# ATxmega16E5 device description
Architecture: AVR8_XMEGA; Family: AVR XMEGA
Registers are 8-bit, access not given, no defined reset value unless marked. A register's access mark holds for its fields unless they carry their own. Offsets are from the block's base; [hi:lo] are bit positions; {n}, {i} and the like mark numbered series; 'fields as' and 'values as' point back to an identical list.

## HIRES — High-Resolution Extension
Instances: HIRESC 0x8B0
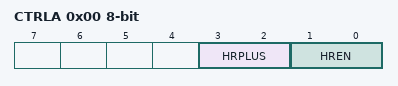
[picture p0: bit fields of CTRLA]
0x00 CTRLA — Control Register A
  [3:2] HRPLUS — High Resolution Plus
    0=NONE (No Hi-Res Plus); 1=HRP4 (Hi-Res Plus enabled on Timer 4); 2=HRP5 (Hi-Res Plus enabled on Timer 5); 3=BOTH (Hi-Res Plus enabled on Timer 4 and 5)
  [1:0] HREN — High Resolution Mode
    0=NONE (No Hi-Res); 1=HRP4 (Hi-Res enabled on Timer 4); 2=HRP5 (Hi-Res enabled on Timer 5); 3=BOTH (Hi-Res enabled on Timer 4 and 5)

## USART — Universal Synchronous/Asynchronous Receiver/Transmitter
Instances: USARTC0 0x8C0, USARTD0 0x9C0
0x00 DATA
0x01 STATUS
  [7] RXCIF — Receive Interrupt Flag
  [6] TXCIF — Transmit Interrupt Flag
  [5] DREIF — Data Register Empty Flag
  [4] FERR — Frame Error
  [3] BUFOVF — Buffer Overflow
  [2] PERR — Parity Error
  [1] RXSIF — Receive Start Bit Interrupt Flag
  [0] RXB8 — Receive Bit 8
  [0] DRIF — Data Reception Flag
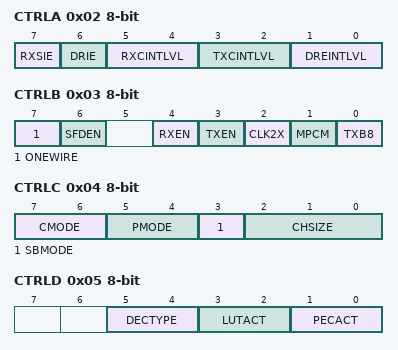
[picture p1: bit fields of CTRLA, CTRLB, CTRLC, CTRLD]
0x02 CTRLA — Control Register A
  [7] RXSIE — Receive Start Interrupt Enable
  [6] DRIE — Data Reception Interrupt Enable
  [5:4] RXCINTLVL — Receive Interrupt Level
    0=OFF (Interrupt Disabled); 1=LO (Low Level); 2=MED (Medium Level); 3=HI (High Level)
  [3:2] TXCINTLVL — Transmit Interrupt Level
    values as RXCINTLVL
  [1:0] DREINTLVL — Data Register Empty Interrupt Level
    values as RXCINTLVL
0x03 CTRLB — Control Register B
  [7] ONEWIRE — One Wire Mode
  [6] SFDEN — Start Frame Detection Enable
  [4] RXEN — Receiver Enable
  [3] TXEN — Transmitter Enable
  [2] CLK2X — Double transmission speed
  [1] MPCM — Multi-processor Communication Mode
  [0] TXB8 — Transmit bit 8
0x04 CTRLC — Control Register C
  [7:6] CMODE — Communication Mode
    0=ASYNCHRONOUS (Asynchronous Mode); 1=SYNCHRONOUS (Synchronous Mode); 2=IRDA (IrDA Mode); 3=MSPI (Master SPI Mode)
  [5:4] PMODE — Parity Mode
    0=DISABLED (No Parity); 2=EVEN (Even Parity); 3=ODD (Odd Parity)
  [3] SBMODE — Stop Bit Mode
  [2:0] CHSIZE — Character Size
    {v}={v+5}BIT (Character size: {v+5} bit) (v=0..3); 7=9BIT (Character size: 9 bit)
0x05 CTRLD — Control Register D
  [5:4] DECTYPE — Receive Interrupt Level
    0=DATA (DATA Field Encoding); 2=SDATA (Start and Data Fields Encoding); 3=NOTSDATA (Start and Data Fields Encoding, with invertion in START field)
  [3:2] LUTACT — Transmit Interrupt Level
    0=OFF (Standard Frame Configuration); 1=RX (Receiver Decoding Enabled); 2=TX (Transmitter Encoding Enabled); 3=BOTH (Both Encoding and Decoding Enabled)
  [1:0] PECACT — Data Register Empty Interrupt Level
    0=OFF (Standard Mode); 1=PEC0 (Variable Data Lenght in Reception); 2=PEC1 (Variable Data Lenght in Transmission); 3=PERC01 (Variable Data Lenght in both Reception and Transmission)
0x06 BAUDCTRLA — Baud Rate Control Register A
  [7:0] BSEL — Baud Rate Selection Bits [7:0]
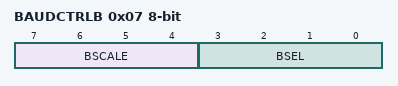
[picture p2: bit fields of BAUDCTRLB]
0x07 BAUDCTRLB — Baud Rate Control Register B
  [7:4] BSCALE — Baud Rate Scale
  [3:0] BSEL — Baud Rate Selection bits[11:8]

## SPI — Serial Peripheral Interface with Buffer Modes
Instances: SPIC 0x08E0
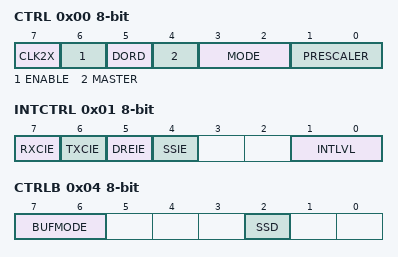
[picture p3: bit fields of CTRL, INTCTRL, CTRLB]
0x00 CTRL — Control Register
  [7] CLK2X — Enable Double Speed
  [6] ENABLE — Enable SPI Module
  [5] DORD — Data Order Setting
  [4] MASTER — Master Operation Enable
  [3:2] MODE — SPI Mode
    0=SPI Mode 0, base clock at "0", sampling on leading edge (rising) & set-up on trailling edge (falling); 1=SPI Mode 1, base clock at "0", set-up on leading edge (rising) & sampling on trailling edge (falling); 2=SPI Mode 2, base clock at "1", sampling on leading edge (falling) & set-up on trailling edge (rising); 3=SPI Mode 3, base clock at "1", set-up on leading edge (falling) & sampling on trailling edge (rising)
  [1:0] PRESCALER
    0=DIV4 (If CLK2X=1 CLKper/2, else (CLK2X=0) CLKper/4.); 1=DIV16 (If CLK2X=1 CLKper/8, else (CLK2X=0) CLKper/16.); 2=DIV64 (If CLK2X=1 CLKper/32, else (CLK2X=0) CLKper/64.); 3=DIV128 (If CLK2X=1 CLKper/64, else (CLK2X=0) CLKper/128.)
0x01 INTCTRL — Interrupt Control Register
  [7] RXCIE — Receive Complete Interrupt Enable (In Buffer Modes Only).
  [6] TXCIE — Transmit Complete Interrupt Enable (In Buffer Modes Only).
  [5] DREIE — Data Register Empty Interrupt Enable (In Buffer Modes Only).
  [4] SSIE — Slave Select Trigger Interrupt Enable (In Buffer Modes Only).
  [1:0] INTLVL — Interrupt level
    0=OFF (Interrupt Disabled); 1=LO (Low Level); 2=MED (Medium Level); 3=HI (High Level)
0x02 STATUS
  [7] IF — Interrupt Flag (In Standard Mode Only).
  [7] RXCIF — Receive Complete Interrupt Flag (In Buffer Modes Only).
  [6] WRCOL — Write Collision Flag (In Standard Mode Only).
  [6] TXCIF — Transmit Complete Interrupt Flag (In Buffer Modes Only).
  [5] DREIF — Data Register Empty Interrupt Flag (In Buffer Modes Only).
  [4] SSIF — Slave Select Trigger Interrupt Flag (In Buffer Modes Only).
  [0] BUFOVF — Buffer Overflow (In Buffer Modes Only).
0x03 DATA
0x04 CTRLB — Control Register B
  [7:6] BUFMODE — Buffer Modes
    0=OFF (SPI Unbuffered Mode); 2=Buffer Mode 1 (with dummy byte); 3=Buffer Mode 2 (no dummy byte)
  [2] SSD — Slave Select Disable

## IRCOM — IR Communication Module
Instances: IRCOM 0x8F8
0x00 CTRL — Control Register
  [3:0] EVSEL — Event Channel Select
    0=OFF (No Event Source); {v}=Event Channel {v-8} (v=8..15)
0x01 TXPLCTRL — IrDA Transmitter Pulse Length Control Register
0x02 RXPLCTRL — IrDA Receiver Pulse Length Control Register

## NVM_LOCKBITS (FUSE module) — Lock Bits
Instances: LOCKBIT 0x00 in lockbits
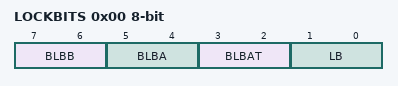
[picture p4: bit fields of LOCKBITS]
0x00 LOCKBITS
  [7:6] BLBB — Boot Lock Bits - Boot Section
    0=RWLOCK (Read and write not allowed); 1=RLOCK (Read not allowed); 2=WLOCK (Write not allowed); 3=NOLOCK (No locks)
  [5:4] BLBA — Boot Lock Bits - Application Section
    values as BLBB
  [3:2] BLBAT — Boot Lock Bits - Application Table
    values as BLBB
  [1:0] LB — Lock Bits
    0=RWLOCK (Read and write not allowed); 2=WLOCK (Write not allowed); 3=NOLOCK (No locks)

## NVM_FUSES — Fuses
Instances: FUSE 0x00 in fuses
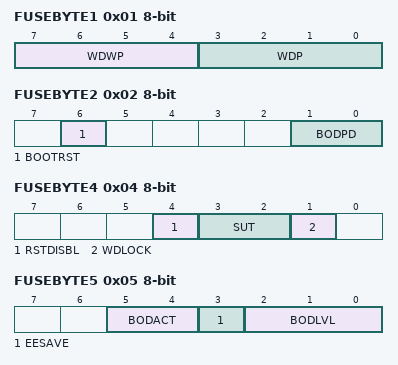
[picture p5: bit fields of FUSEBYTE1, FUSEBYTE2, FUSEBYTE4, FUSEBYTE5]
0x01 FUSEBYTE1 — Watchdog Configuration
  [7:4] WDWP — Watchdog Window Timeout Period
    0=8CLK (8 cycles (8ms @ 3.3V)); 1=16CLK (16 cycles (16ms @ 3.3V)); 2=32CLK (32 cycles (32ms @ 3.3V)); 3=64CLK (64 cycles (64ms @ 3.3V)); 4=128CLK (128 cycles (0.125s @ 3.3V)); 5=256CLK (256 cycles (0.25s @ 3.3V)); 6=512CLK (512 cycles (0.5s @ 3.3V)); 7=1KCLK (1K cycles (1s @ 3.3V)); 8=2KCLK (2K cycles (2s @ 3.3V)); 9=4KCLK (4K cycles (4s @ 3.3V)); 10=8KCLK (8K cycles (8s @ 3.3V))
  [3:0] WDP — Watchdog Timeout Period
    values as WDWP
0x02 FUSEBYTE2 — Reset Configuration
  [6] BOOTRST — Boot Loader Section Reset Vector
    0=BOOTLDR (Boot Loader Reset); 1=APPLICATION (Application Reset)
  [1:0] BODPD — BOD Operation in Power-Down Mode
    1=SAMPLED (BOD enabled in sampled mode); 2=CONTINUOUS (BOD enabled continuously); 3=DISABLED (BOD Disabled)
0x04 FUSEBYTE4 — Start-up Configuration
  [4] RSTDISBL — External Reset Disable
  [3:2] SUT — Start-up Time
    3=0MS; 1=4MS; 0=64MS
  [1] WDLOCK — Watchdog Timer Lock
0x05 FUSEBYTE5 — EESAVE and BOD Level
  [5:4] BODACT — BOD Operation in Active Mode
    values as FUSEBYTE2.BODPD
  [3] EESAVE — Preserve EEPROM Through Chip Erase
  [2:0] BODLVL — Brownout Detection Voltage Level
    7=1V6 (1.6 V); 6=1V8 (1.8 V); 5=2V0 (2.0 V); 4=2V2 (2.2 V); 3=2V4 (2.4 V); 2=2V6 (2.6 V); 1=2V8 (2.8 V); 0=3V0 (3.0 V)
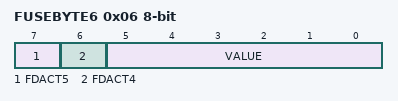
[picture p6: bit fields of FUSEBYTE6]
0x06 FUSEBYTE6 — Fault State
  [7] FDACT5 — Fault Dectection Action on TC5
  [6] FDACT4 — Fault Dectection Action on TC4
  [5:0] VALUE — Port Pin Value

## NVM_PROD_SIGNATURES (SIGROW module) — Production Signatures
Instances: PROD_SIGNATURES 0x00 in prod_signatures
0x00 RCOSC8M — RCOSC 8MHz Calibration Value
0x02 RCOSC32K — RCOSC 32.768 kHz Calibration Value
0x03 RCOSC32M — RCOSC 32 MHz Calibration Value B
0x04 RCOSC32MA — RCOSC 32 MHz Calibration Value A
{0x8+i} LOTNUM{i} (i=0..5) — Lot Number Byte {i}, ASCII
0x10 WAFNUM — Wafer Number
0x12 COORDX0 — Wafer Coordinate X Byte 0
0x13 COORDX1 — Wafer Coordinate X Byte 1
0x14 COORDY0 — Wafer Coordinate Y Byte 0
0x15 COORDY1 — Wafer Coordinate Y Byte 1
0x1E ROOMTEMP — Temperature corresponds to TEMPSENSE3/2
0x1F HOTTEMP — Temperature corresponds to TEMPSENSE1/0
0x20 ADCACAL0 — ADCA Calibration Byte 0
0x21 ADCACAL1 — ADCA Calibration Byte 1
0x28 ACACURRCAL — ACA Current Calibration Byte
0x2C TEMPSENSE2 — Temperature Sensor Calibration Byte 2
0x2D TEMPSENSE3 — Temperature Sensor Calibration Byte 3
0x2E TEMPSENSE0 — Temperature Sensor Calibration Byte 0
0x2F TEMPSENSE1 — Temperature Sensor Calibration Byte 1
0x30 DACA0OFFCAL — DACA0 Calibration Byte 0
0x31 DACA0GAINCAL — DACA0 Calibration Byte 1
0x34 DACA1OFFCAL — DACA1 Calibration Byte 0
0x35 DACA1GAINCAL — DACA1 Calibration Byte 1
